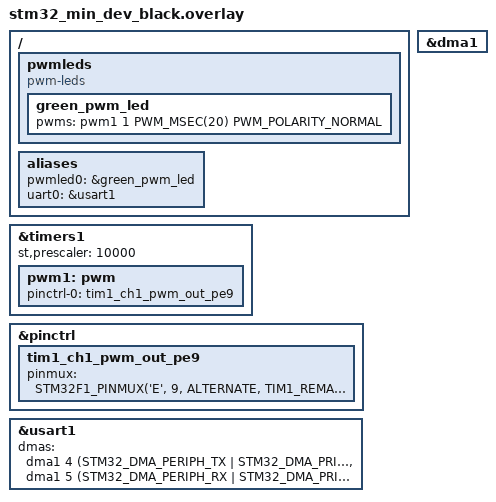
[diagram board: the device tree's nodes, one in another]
/*
 * SPDX-License-Identifier: Apache-2.0
 *
 * Copyright (c) 2022 STMicroelectronics
 */


/ {
	pwmleds: pwmleds {
		compatible = "pwm-leds";
		status = "okay";

		green_pwm_led: green_pwm_led {
			pwms = <&pwm1 1 PWM_MSEC(20) PWM_POLARITY_NORMAL>;
		};
	};

	aliases {
		pwmled0 = &green_pwm_led;
		uart0 = &usart1;
	};

};

&timers1 {
	status = "okay";
	st,prescaler = <10000>;

	pwm1: pwm {
		status = "okay";
		pinctrl-0 = <&tim1_ch1_pwm_out_pe9>;
		pinctrl-names = "default";
	};
};

&pinctrl {
	/omit-if-no-ref/ tim1_ch1_pwm_out_pe9: tim1_ch1_pwm_out_pe9 {
				pinmux = <STM32F1_PINMUX('E', 9, ALTERNATE, TIM1_REMAP2)>;
			};
};

&usart1 {
	dmas = <&dma1 4 (STM32_DMA_PERIPH_TX | STM32_DMA_PRIORITY_HIGH)>,
	       <&dma1 5 (STM32_DMA_PERIPH_RX | STM32_DMA_PRIORITY_HIGH)>;
	dma-names = "tx", "rx";
};

&dma1 {
	status = "okay";
};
